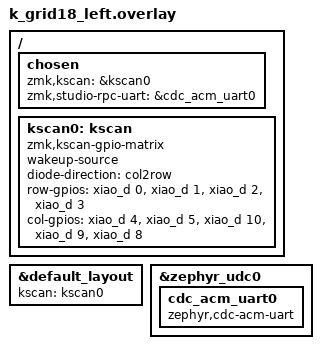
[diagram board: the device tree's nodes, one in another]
#include "k_grid18.dtsi"

/ {
    chosen {
        zmk,kscan = &kscan0;
        zmk,studio-rpc-uart = &cdc_acm_uart0;
    };

    kscan0: kscan {
        compatible = "zmk,kscan-gpio-matrix";
        wakeup-source;
        diode-direction = "col2row";
        row-gpios
            = <&xiao_d 0 (GPIO_ACTIVE_HIGH | GPIO_PULL_DOWN)>
            , <&xiao_d 1 (GPIO_ACTIVE_HIGH | GPIO_PULL_DOWN)>
            , <&xiao_d 2 (GPIO_ACTIVE_HIGH | GPIO_PULL_DOWN)>
            , <&xiao_d 3 (GPIO_ACTIVE_HIGH | GPIO_PULL_DOWN)>
            ;
        col-gpios
            = <&xiao_d 4 GPIO_ACTIVE_HIGH>
            , <&xiao_d 5 GPIO_ACTIVE_HIGH>
            , <&xiao_d 10 GPIO_ACTIVE_HIGH>
            , <&xiao_d 9 GPIO_ACTIVE_HIGH>
            , <&xiao_d 8 GPIO_ACTIVE_HIGH>
            ;
    };
};
&default_layout {
    kscan = <&kscan0>;
};
&zephyr_udc0 {
    cdc_acm_uart0: cdc_acm_uart0 {
        compatible = "zephyr,cdc-acm-uart";
    };
};
